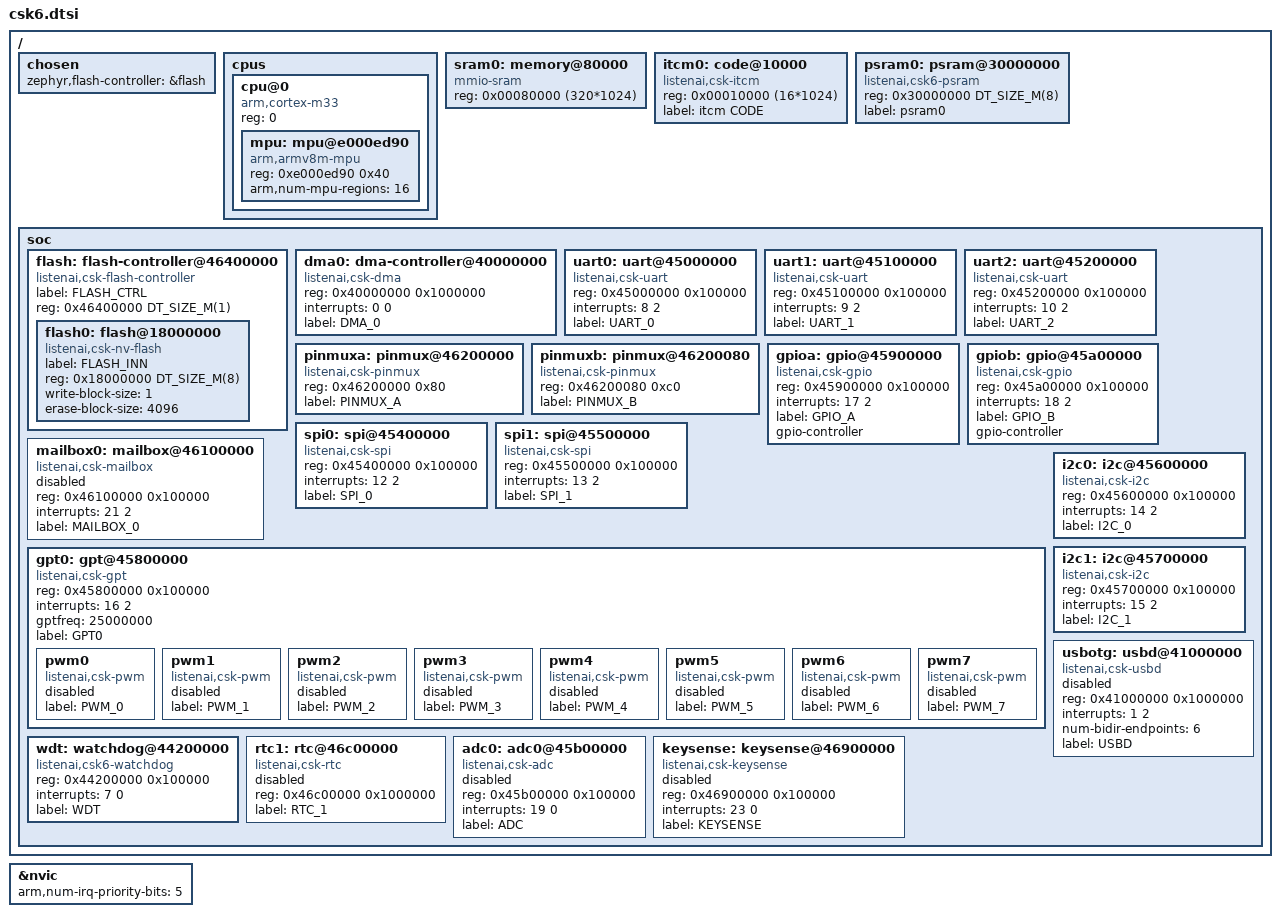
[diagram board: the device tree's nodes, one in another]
/* SPDX-License-Identifier: Apache-2.0 */

#include <mem.h>
#include <arm/armv8-m.dtsi>


/ {
	chosen {
		zephyr,flash-controller = &flash;
	};
	cpus {
		#address-cells = <1>;
		#size-cells = <0>;

		cpu@0 {
			device_type = "cpu";
			compatible = "arm,cortex-m33";
			reg = <0>;
			#address-cells = <1>;
			#size-cells = <1>;
			
			mpu: mpu@e000ed90 {
				compatible = "arm,armv8m-mpu";
				reg = <0xe000ed90 0x40>;
				arm,num-mpu-regions = <16>;
			};

		};
	};

	sram0: memory@80000 {
		compatible = "mmio-sram";
		reg = <0x00080000 (320*1024)>;
	};

    itcm0: code@10000 {
        compatible = "listenai,csk-itcm";
        reg = <0x00010000 (16*1024)>;
        label = "itcm CODE";
    };

	psram0: psram@30000000 {
		compatible = "listenai,csk6-psram";
		reg = <0x30000000 DT_SIZE_M(8)>;
		label = "psram0";
	};	

	soc {

		flash: flash-controller@46400000 {
			compatible = "listenai,csk-flash-controller";
			label = "FLASH_CTRL";
			reg = <0x46400000 DT_SIZE_M(1)>;
			#address-cells = <1>;
			#size-cells = <1>;


			flash0: flash@18000000 {
				compatible = "listenai,csk-nv-flash","soc-nv-flash";
				label = "FLASH_INN";
				reg = <0x18000000 DT_SIZE_M(8)>;
				write-block-size = <1>;
				erase-block-size = <4096>;
			};

		};

		dma0: dma-controller@40000000 {
			compatible = "listenai,csk-dma";
			reg = <0x40000000 0x1000000>;
			interrupts = <0 0>;
			label = "DMA_0";
			#dma-cells = <1>;
		};

		uart0: uart@45000000 {
			compatible = "listenai,csk-uart";
			reg = <0x45000000 0x100000>;
			interrupts = <8 2>;
			label = "UART_0";
		};

		uart1: uart@45100000 {
			compatible = "listenai,csk-uart";
			reg = <0x45100000 0x100000>;
			interrupts = <9 2>;
			label = "UART_1";
		};

		uart2: uart@45200000 {
			compatible = "listenai,csk-uart";
			reg = <0x45200000 0x100000>;
			interrupts = <10 2>;
			label = "UART_2";
		};

		pinmuxa: pinmux@46200000 {
			compatible = "listenai,csk-pinmux";
			reg = <0x46200000 0x80>;
			#pinmux-cells = <2>;
			#pinctrl-cells = <2>;
			label = "PINMUX_A";
			status = "okay";
		};

		pinmuxb: pinmux@46200080 {
			compatible = "listenai,csk-pinmux";
			reg = <0x46200080 0xc0>;
			#pinmux-cells = <2>;
			#pinctrl-cells = <2>;
			label = "PINMUX_B";
			status = "okay";
		};

		gpioa: gpio@45900000 {
			compatible = "listenai,csk-gpio";
			reg = <0x45900000 0x100000>;
			interrupts = <17 2>;
			label = "GPIO_A";
			gpio-controller;
			#gpio-cells = <2>;
		};

		gpiob: gpio@45a00000 {
			compatible = "listenai,csk-gpio";
			reg = <0x45a00000 0x100000>;
			interrupts = <18 2>;
			label = "GPIO_B";
			gpio-controller;
			#gpio-cells = <2>;
		};

		spi0: spi@45400000 {
			compatible = "listenai,csk-spi";
			reg = <0x45400000 0x100000>;
			interrupts = <12 2>;
			label = "SPI_0";
			#address-cells = <1>;
			#size-cells = <0>;
		};

        spi1: spi@45500000 {
            compatible = "listenai,csk-spi";
            reg = <0x45500000 0x100000>;
            interrupts = <13 2>;
            label = "SPI_1";
            #address-cells = <1>;
            #size-cells = <0>;
        };

		mailbox0: mailbox@46100000 {
			compatible = "listenai,csk-mailbox";
			reg = <0x46100000 0x100000>;
			interrupts = <21 2>;
			label = "MAILBOX_0";
			status = "disabled";
		};

		gpt0: gpt@45800000 {
			compatible = "listenai,csk-gpt";
			reg = <0x45800000 0x100000>;
			interrupts = <16 2>;
			gptfreq = <25000000>;
			label = "GPT0";

			pwm0 {
				compatible = "listenai,csk-pwm";
				status = "disabled";
				label = "PWM_0";
				#pwm-cells = <2>;
			};

			pwm1 {
				compatible = "listenai,csk-pwm";
				status = "disabled";
				label = "PWM_1";
				#pwm-cells = <2>;
			};

			pwm2 {
				compatible = "listenai,csk-pwm";
				status = "disabled";
				label = "PWM_2";
				#pwm-cells = <2>;
			};

			pwm3 {
				compatible = "listenai,csk-pwm";
				status = "disabled";
				label = "PWM_3";
				#pwm-cells = <2>;
			};

			pwm4 {
				compatible = "listenai,csk-pwm";
				status = "disabled";
				label = "PWM_4";
				#pwm-cells = <2>;
			};

			pwm5 {
				compatible = "listenai,csk-pwm";
				status = "disabled";
				label = "PWM_5";
				#pwm-cells = <2>;
			};

			pwm6 {
				compatible = "listenai,csk-pwm";
				status = "disabled";
				label = "PWM_6";
				#pwm-cells = <2>;
			};

			pwm7 {
				compatible = "listenai,csk-pwm";
				status = "disabled";
				label = "PWM_7";
				#pwm-cells = <2>;
			};
		};
		
		i2c0: i2c@45600000 {
			compatible = "listenai,csk-i2c";
			reg = <0x45600000 0x100000>;
			interrupts = <14 2>;
			#address-cells = <1>;
			#size-cells = <0>;
			label = "I2C_0";
		};

		i2c1: i2c@45700000 {
			compatible = "listenai,csk-i2c";
			reg = <0x45700000 0x100000>;
			interrupts = <15 2>;
			#address-cells = <1>;
			#size-cells = <0>;
			label = "I2C_1";
		};
		
		usbotg: usbd@41000000 {
			compatible = "listenai,csk-usbd";
			reg = <0x41000000 0x1000000>;
			interrupts = <1 2>;
			interrupt-names = "usb_otg";
			num-bidir-endpoints = <6>;
			status = "disabled";
			label = "USBD";
		};

		wdt: watchdog@44200000 {
			compatible = "listenai,csk6-watchdog";
			reg = <0x44200000 0x100000>;
			interrupts = <7 0>;
			label = "WDT";
			status = "okay";
		};

		rtc1: rtc@46c00000 {
			compatible = "listenai,csk-rtc";
			reg = <0x46c00000 0x1000000>;
			status = "disabled";
			label = "RTC_1";
		};

		adc0: adc0@45b00000 {
			compatible = "listenai,csk-adc";
			reg = <0x45b00000 0x100000>;
			interrupts = <19 0>;
			status = "disabled";
			label = "ADC";
			#io-channel-cells = <1>;
		};

		keysense: keysense@46900000{
			compatible = "listenai,csk-keysense";
			reg = <0x46900000 0x100000>;
			interrupts = <23 0>;
			status = "disabled";
			label = "KEYSENSE";
		};

	};
};

&nvic {
	arm,num-irq-priority-bits = <5>;
};
